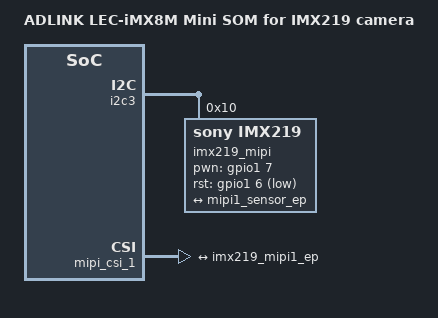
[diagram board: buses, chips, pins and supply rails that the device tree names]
/*
 *
 */


#include "lec-imx8mm.dts"

/{
	model = "ADLINK LEC-iMX8M Mini SOM for IMX219 camera";
};

&i2c3 {

	/delete-node/ ov5640_mipi@3c;
	
	imx219_mipi: imx219_mipi@10 {
		compatible = "sony,imx219";
		reg = <0x10>;
		status = "okay";
		pinctrl-names = "default";
		pinctrl-0 = <&pinctrl_csi_pwn>, <&pinctrl_csi_rst>;
		clocks = <&clk IMX8MM_CLK_CLKO1>;
		clock-names = "csi_mclk";
		assigned-clocks = <&clk IMX8MM_CLK_CLKO1>;
		assigned-clock-parents = <&clk IMX8MM_CLK_24M>;
		assigned-clock-rates = <24000000>;
		csi_id = <0>;
		pwn-gpios = <&gpio1 7 GPIO_ACTIVE_HIGH>;
		rst-gpios = <&gpio1 6 GPIO_ACTIVE_LOW>;
		mclk = <24000000>;
		mclk_source = <0>;
		port {
			imx219_mipi1_ep: endpoint {
				remote-endpoint = <&mipi1_sensor_ep>;
				data-lanes = <1 2>;
				clock-lanes = <0>;
				clock-noncontinuous;
				link-frequencies = /bits/ 64 <456000000>;
			};
		};
	};
};

&mipi_csi_1 {
	/delete-node/ endpoint@1;
	port {
		mipi1_sensor_ep: endpoint@1 {
			remote-endpoint = <&imx219_mipi1_ep>;
			data-lanes = <2>;
			csis-hs-settle = <13>;
			csis-clk-settle = <2>;
			csis-wclk;
			clock-noncontinuous;
		};

	};
};

